# STM32F745IEK6 register map
File version: 1.0
Registers are 32-bit, access not given, reset 0x0 unless marked. A register's access mark holds for its fields unless they carry their own. Offsets are from the block's base; [hi:lo] are bit positions; {n}, {i} and the like mark numbered series.

## CAN1
Base 0x40006400
Same registers: CAN2 0x40006800
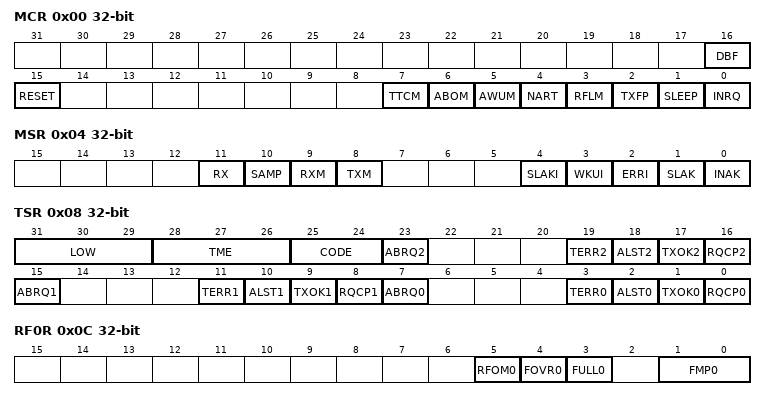
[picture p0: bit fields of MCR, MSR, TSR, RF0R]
0x00 MCR
  [16] DBF, [15] RESET, [7] TTCM, [6] ABOM, [5] AWUM, [4] NART, [3] RFLM, [2] TXFP, [1] SLEEP, [0] INRQ
0x04 MSR
  [11] RX, [10] SAMP, [9] RXM, [8] TXM, [4] SLAKI, [3] WKUI, [2] ERRI, [1] SLAK, [0] INAK
0x08 TSR
  [31:29] LOW, [28:26] TME, [25:24] CODE, [23] ABRQ2, [19] TERR2, [18] ALST2, [17] TXOK2, [16] RQCP2, [15] ABRQ1, [11] TERR1, [10] ALST1, [9] TXOK1, [8] RQCP1, [7] ABRQ0, [3] TERR0, [2] ALST0, [1] TXOK0, [0] RQCP0
0x0C RF0R
  [5] RFOM0, [4] FOVR0, [3] FULL0, [1:0] FMP0
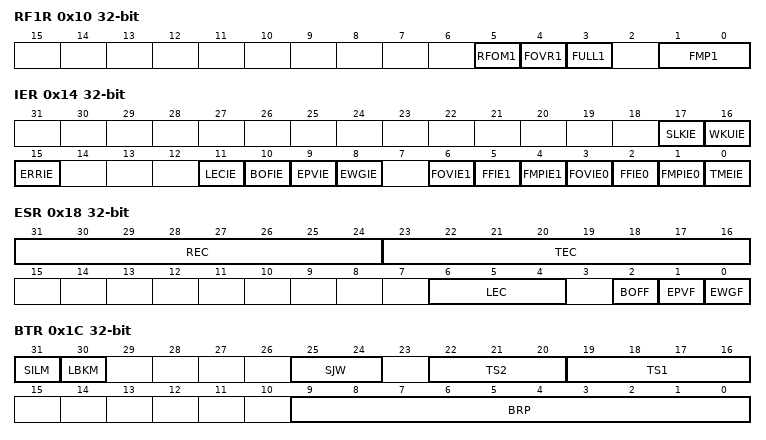
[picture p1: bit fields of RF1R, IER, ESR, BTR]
0x10 RF1R
  [5] RFOM1, [4] FOVR1, [3] FULL1, [1:0] FMP1
0x14 IER
  [17] SLKIE, [16] WKUIE, [15] ERRIE, [11] LECIE, [10] BOFIE, [9] EPVIE, [8] EWGIE, [6] FOVIE1, [5] FFIE1, [4] FMPIE1, [3] FOVIE0, [2] FFIE0, [1] FMPIE0, [0] TMEIE
0x18 ESR
  [31:24] REC, [23:16] TEC, [6:4] LEC, [2] BOFF, [1] EPVF, [0] EWGF
0x1C BTR
  [31] SILM, [30] LBKM, [25:24] SJW, [22:20] TS2, [19:16] TS1, [9:0] BRP
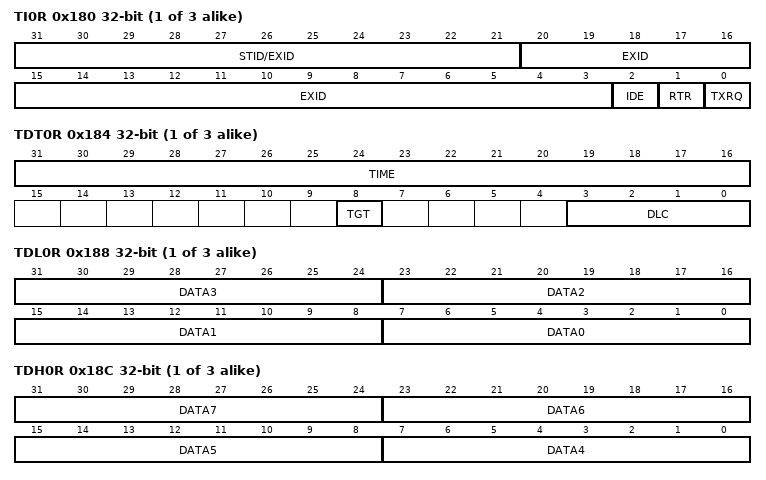
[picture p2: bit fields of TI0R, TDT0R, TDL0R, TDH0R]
{0x180+0x10*i} TI{i}R (i=0..2)
  [31:21] STID/EXID, [20:3] EXID, [2] IDE, [1] RTR, [0] TXRQ
{0x184+0x10*i} TDT{i}R (i=0..2)
  [31:16] TIME, [8] TGT, [3:0] DLC
{0x188+0x10*i} TDL{i}R (i=0..2)
  [8n+7:8n] DATA{n} (n=0..3)
{0x18C+0x10*i} TDH{i}R (i=0..2)
  [8n-25:8n-32] DATA{n} (n=4..7)
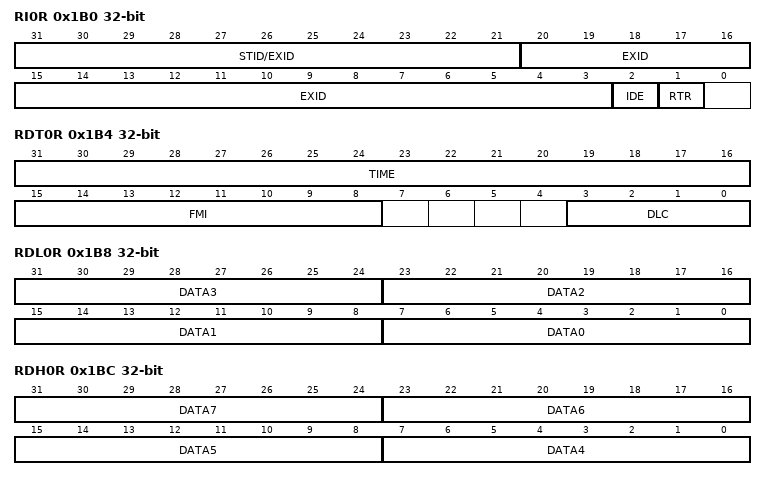
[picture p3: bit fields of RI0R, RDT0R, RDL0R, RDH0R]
0x1B0 RI0R
  [31:21] STID/EXID, [20:3] EXID, [2] IDE, [1] RTR
0x1B4 RDT0R
  [31:16] TIME, [15:8] FMI, [3:0] DLC
0x1B8 RDL0R
  [8n+7:8n] DATA{n} (n=0..3)
0x1BC RDH0R
  [8n-25:8n-32] DATA{n} (n=4..7)
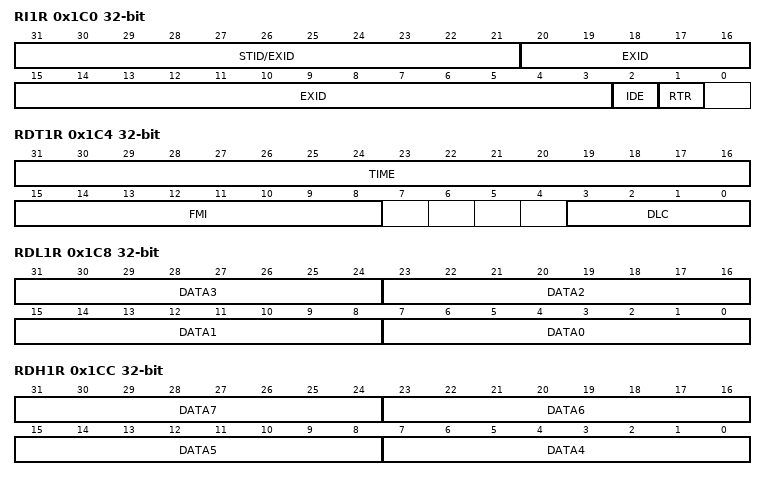
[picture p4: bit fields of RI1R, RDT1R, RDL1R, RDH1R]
0x1C0 RI1R
  [31:21] STID/EXID, [20:3] EXID, [2] IDE, [1] RTR
0x1C4 RDT1R
  [31:16] TIME, [15:8] FMI, [3:0] DLC
0x1C8 RDL1R
  [8n+7:8n] DATA{n} (n=0..3)
0x1CC RDH1R
  [8n-25:8n-32] DATA{n} (n=4..7)
0x20C FS1R
  [27:0] FSC
0x214 FFA1R
  [27:0] FFA
0x21C FA1R
  [27:0] FACT
{0x240+8i} F{i}R1 (i=0..27)
  [31:0] FB
{0x244+8i} F{i}R2 (i=0..27)
  [31:0] FB

## CEC
Base 0x40006C00
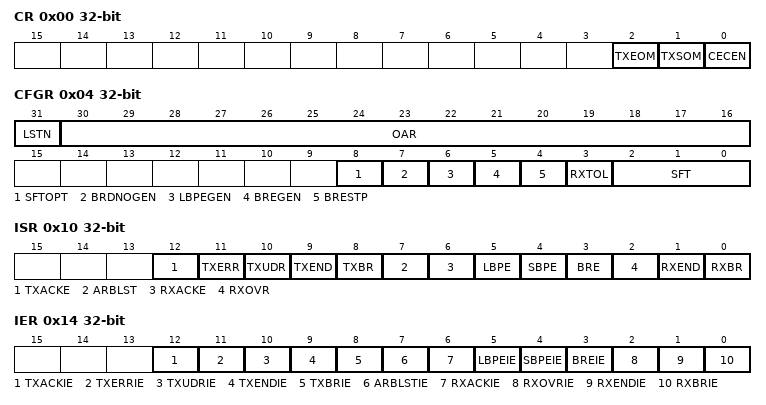
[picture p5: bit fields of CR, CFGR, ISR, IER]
0x00 CR
  [2] TXEOM, [1] TXSOM, [0] CECEN
0x04 CFGR
  [31] LSTN, [30:16] OAR, [8] SFTOPT, [7] BRDNOGEN, [6] LBPEGEN, [5] BREGEN, [4] BRESTP, [3] RXTOL, [2:0] SFT
0x08 TXDR
  [7:0] TXD
0x0C RXDR
  [7:0] RXD
0x10 ISR
  [12] TXACKE, [11] TXERR, [10] TXUDR, [9] TXEND, [8] TXBR, [7] ARBLST, [6] RXACKE, [5] LBPE, [4] SBPE, [3] BRE, [2] RXOVR, [1] RXEND, [0] RXBR
0x14 IER
  [12] TXACKIE, [11] TXERRIE, [10] TXUDRIE, [9] TXENDIE, [8] TXBRIE, [7] ARBLSTIE, [6] RXACKIE, [5] LBPEIE, [4] SBPEIE, [3] BREIE, [2] RXOVRIE, [1] RXENDIE, [0] RXBRIE

## PWR
Base 0x40007000
0x00 CR1
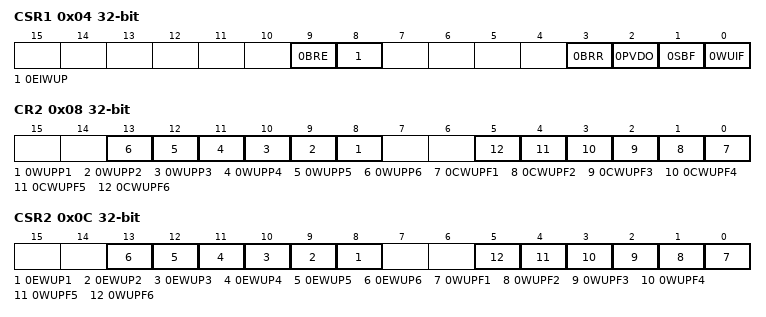
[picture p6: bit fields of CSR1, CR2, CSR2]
0x04 CSR1
  [9] 0BRE, [8] 0EIWUP, [3] 0BRR, [2] 0PVDO, [1] 0SBF, [0] 0WUIF
0x08 CR2
  [n+7] 0WUPP{n} (n=1..6), [n-1] 0CWUPF{n} (n=1..6)
0x0C CSR2
  [n+7] 0EWUP{n} (n=1..6), [n-1] 0WUPF{n} (n=1..6)

## DAC
Base 0x40007400
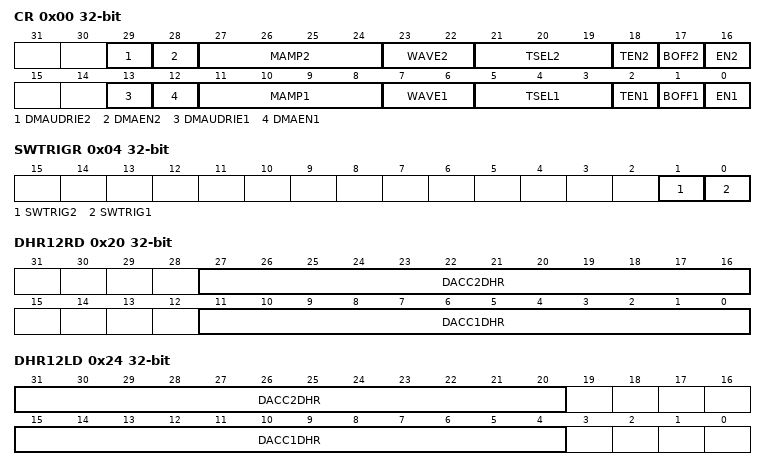
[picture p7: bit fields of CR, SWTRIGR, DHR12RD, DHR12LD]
0x00 CR
  [29] DMAUDRIE2, [28] DMAEN2, [27:24] MAMP2, [23:22] WAVE2, [21:19] TSEL2, [18] TEN2, [17] BOFF2, [16] EN2, [13] DMAUDRIE1, [12] DMAEN1, [11:8] MAMP1, [7:6] WAVE1, [5:3] TSEL1, [2] TEN1, [1] BOFF1, [0] EN1
0x04 SWTRIGR
  [1] SWTRIG2, [0] SWTRIG1
0x08 DHR12R1
  [11:0] DACC1DHR
0x0C DHR12L1
  [15:4] DACC1DHR
0x10 DHR8R1
  [7:0] DACC1DHR
0x14 DHR12R2
  [11:0] DACC2DHR
0x18 DHR12L2
  [15:4] DACC2DHR
0x1C DHR8R2
  [7:0] DACC2DHR
0x20 DHR12RD
  [27:16] DACC2DHR, [11:0] DACC1DHR
0x24 DHR12LD
  [31:20] DACC2DHR, [15:4] DACC1DHR
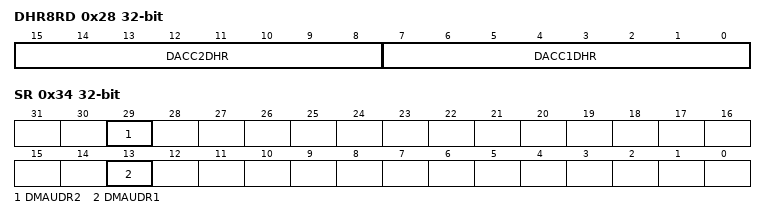
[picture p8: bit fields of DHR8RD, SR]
0x28 DHR8RD
  [15:8] DACC2DHR, [7:0] DACC1DHR
0x2C DOR1
  [11:0] DACC1DOR
0x30 DOR2
  [11:0] DACC2DOR
0x34 SR
  [29] DMAUDR2, [13] DMAUDR1

## TIM1
Base 0x40010000
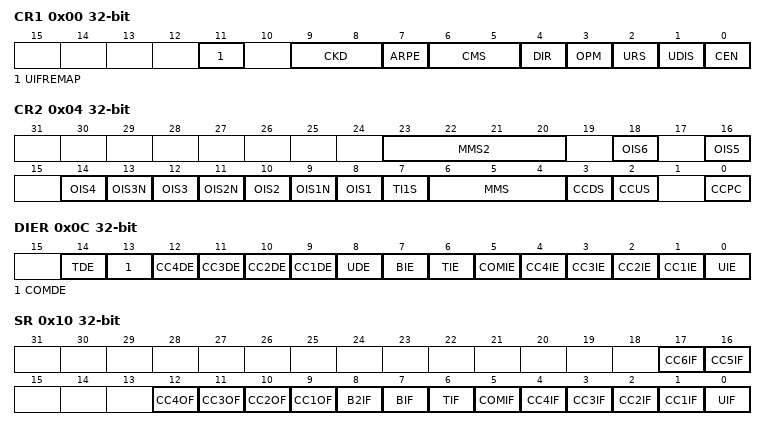
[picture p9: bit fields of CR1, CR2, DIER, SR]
0x00 CR1
  [11] UIFREMAP, [9:8] CKD, [7] ARPE, [6:5] CMS, [4] DIR, [3] OPM, [2] URS, [1] UDIS, [0] CEN
0x04 CR2
  [23:20] MMS2, [2n+6] OIS{n} (n=1..6), [13] OIS3N, [11] OIS2N, [9] OIS1N, [7] TI1S, [6:4] MMS, [3] CCDS, [2] CCUS, [0] CCPC
0x08 SMCR
  [15] ETP, [14] ECE, [13:12] ETPS, [11:8] ETF, [7] MSM, [6:4] TS, [16:0] SMS
0x0C DIER
  [14] TDE, [13] COMDE, [n+8] CC{n}DE (n=1..4), [8] UDE, [7] BIE, [6] TIE, [5] COMIE, [n] CC{n}IE (n=1..4), [0] UIE
0x10 SR
  [17] CC6IF, [16] CC5IF, [n+8] CC{n}OF (n=1..4), [8] B2IF, [7] BIF, [6] TIF, [5] COMIF, [n] CC{n}IF (n=1..4), [0] UIF
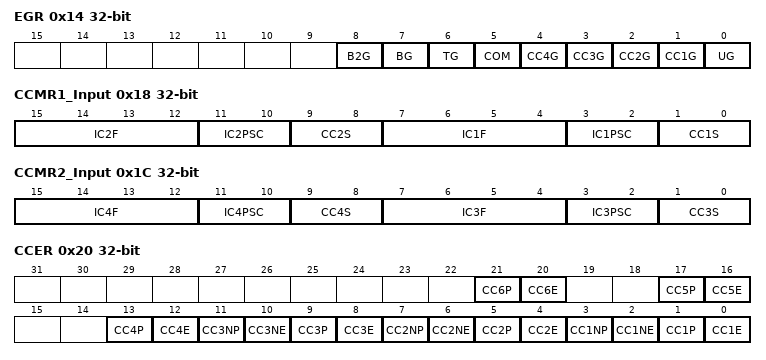
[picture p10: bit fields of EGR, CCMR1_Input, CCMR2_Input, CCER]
0x14 EGR
  [8] B2G, [7] BG, [6] TG, [5] COM, [n] CC{n}G (n=1..4), [0] UG
0x18 CCMR1_Output
  [15] OC2CE, [24:12] OC2M, [11] OC2PE, [10] OC2FE, [9:8] CC2S, [7] OC1CE, [16:4] OC1M, [3] OC1PE, [2] OC1FE, [1:0] CC1S
0x18 CCMR1_Input
  [15:12] IC2F, [11:10] IC2PSC, [9:8] CC2S, [7:4] IC1F, [3:2] IC1PSC, [1:0] CC1S
0x1C CCMR2_Output
  [15] OC4CE, [24:12] OC4M, [11] OC4PE, [10] OC4FE, [9:8] CC4S, [7] OC3CE, [16:4] OC3M, [3] OC3PE, [2] OC3FE, [1:0] CC3S
0x1C CCMR2_Input
  [15:12] IC4F, [11:10] IC4PSC, [9:8] CC4S, [7:4] IC3F, [3:2] IC3PSC, [1:0] CC3S
0x20 CCER
  [4n-3] CC{n}P (n=1..6), [4n-4] CC{n}E (n=1..6), [11] CC3NP, [10] CC3NE, [7] CC2NP, [6] CC2NE, [3] CC1NP, [2] CC1NE
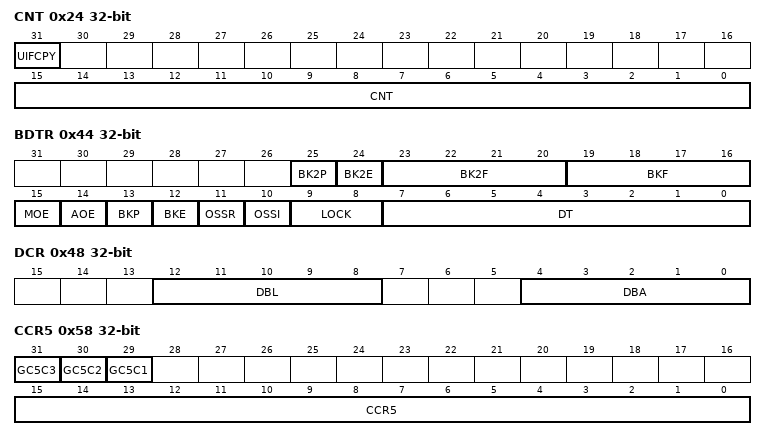
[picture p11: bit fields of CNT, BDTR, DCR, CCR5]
0x24 CNT
  [31] UIFCPY, [15:0] CNT
0x28 PSC
  [15:0] PSC
0x2C ARR
  [15:0] ARR
0x30 RCR
  [15:0] REP
{0x30+4i} CCR{i} (i=1..4)
  [15:0] CCR{i}
0x44 BDTR
  [25] BK2P, [24] BK2E, [23:20] BK2F, [19:16] BKF, [15] MOE, [14] AOE, [13] BKP, [12] BKE, [11] OSSR, [10] OSSI, [9:8] LOCK, [7:0] DT
0x48 DCR
  [12:8] DBL, [4:0] DBA
0x4C DMAR
  [15:0] DMAB
0x54 CCMR3_Output
  [15] OC6CE, [24:12] OC6M, [11] OC6PE, [10] OC6FE, [7] OC5CE, [16:4] OC5M, [3] OC5PE, [2] OC5FE
0x58 CCR5
  [31] GC5C3, [30] GC5C2, [29] GC5C1, [15:0] CCR5
0x5C CCR6
  [15:0] CCR6

## TIM8
Base 0x40010400
Registers as TIM1; these are added or differ:
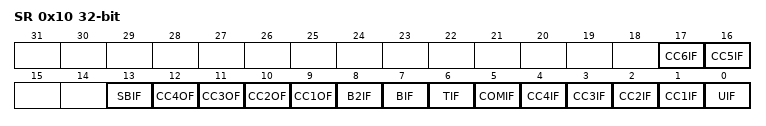
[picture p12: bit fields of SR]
0x10 SR
  [17] CC6IF, [16] CC5IF, [13] SBIF, [n+8] CC{n}OF (n=1..4), [8] B2IF, [7] BIF, [6] TIF, [5] COMIF, [n] CC{n}IF (n=1..4), [0] UIF
